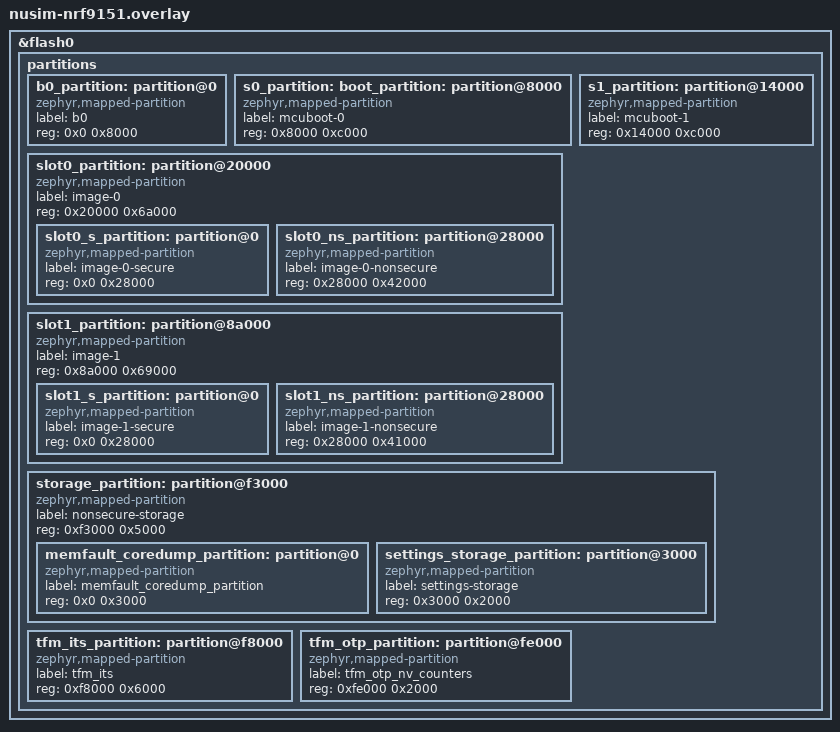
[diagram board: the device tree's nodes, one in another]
/*
 * Copyright (c) 2026 Nordic Semiconductor ASA
 *
 * SPDX-License-Identifier: LicenseRef-Nordic-5-Clause
 */

/*
 * Flash partition layout for nRF9151 DK with nuSIM (same with MCUboot and application).
 * The application SRAM layout for nuSIM is in nusim-sram-nrf9151.overlay.
 *
 * 0x0000_0000  b0 (NSIB)                    ( 32 kB)
 * 0x0000_8000  s0 (MCUboot image, slot 0)   ( 48 kB)
 * 0x0001_4000  s1 (MCUboot image, slot 1)   ( 48 kB)
 * 0x0002_0000  slot0 (primary app)          (424 kB)
 *   0x0002_0000  TF-M secure                (160 kB)
 *   0x0004_8000  Application (non-secure)   (264 kB - (MCUboot swap sector + MCUboot trailer))
 * 0x0008_a000  slot1 (secondary app)        (420 kB)
 * 0x000f_3000  storage (container)          ( 20 kB)
 *   0x000f_3000  Memfault core dump         ( 12 kB)
 *   0x000f_6000  Settings storage           (  8 kB)
 * 0x000f_8000  TF-M ITS                     ( 24 kB)
 * 0x000f_e000  TF-M OTP / NV counters       (  8 kB)
 */

&flash0 {
	/delete-node/ partitions;

	partitions {
		#address-cells = <1>;
		#size-cells = <1>;
		ranges;

		b0_partition: partition@0 {
			compatible = "zephyr,mapped-partition";
			label = "b0";
			reg = <0x0 0x8000>;
		};

		s0_partition: boot_partition: partition@8000 {
			compatible = "zephyr,mapped-partition";
			label = "mcuboot-0";
			reg = <0x8000 0xc000>;
		};

		s1_partition: partition@14000 {
			compatible = "zephyr,mapped-partition";
			label = "mcuboot-1";
			reg = <0x14000 0xc000>;
		};

		slot0_partition: partition@20000 {
			compatible = "zephyr,mapped-partition";
			label = "image-0";
			reg = <0x20000 0x6a000>;
			ranges = <0x0 0x20000 0x6a000>;
			#address-cells = <1>;
			#size-cells = <1>;

			slot0_s_partition: partition@0 {
				compatible = "zephyr,mapped-partition";
				label = "image-0-secure";
				reg = <0x0 0x28000>;
			};

			slot0_ns_partition: partition@28000 {
				compatible = "zephyr,mapped-partition";
				label = "image-0-nonsecure";
				reg = <0x28000 0x42000>;
			};
		};

		slot1_partition: partition@8a000 {
			compatible = "zephyr,mapped-partition";
			label = "image-1";
			reg = <0x8a000 0x69000>;
			ranges = <0x0 0x8a000 0x69000>;
			#address-cells = <1>;
			#size-cells = <1>;

			slot1_s_partition: partition@0 {
				compatible = "zephyr,mapped-partition";
				label = "image-1-secure";
				reg = <0x0 0x28000>;
			};

			slot1_ns_partition: partition@28000 {
				compatible = "zephyr,mapped-partition";
				label = "image-1-nonsecure";
				reg = <0x28000 0x41000>;
			};
		};

		storage_partition: partition@f3000 {
			compatible = "zephyr,mapped-partition";
			label = "nonsecure-storage";
			reg = <0xf3000 0x5000>;
			ranges = <0x0 0xf3000 0x5000>;
			#address-cells = <1>;
			#size-cells = <1>;

			memfault_coredump_partition: partition@0 {
				compatible = "zephyr,mapped-partition";
				label = "memfault_coredump_partition";
				reg = <0x0 0x3000>;
			};

			settings_storage_partition: partition@3000 {
				compatible = "zephyr,mapped-partition";
				label = "settings-storage";
				reg = <0x3000 0x2000>;
			};
		};

		tfm_its_partition: partition@f8000 {
			compatible = "zephyr,mapped-partition";
			label = "tfm_its";
			reg = <0xf8000 0x6000>;
		};

		tfm_otp_partition: partition@fe000 {
			compatible = "zephyr,mapped-partition";
			label = "tfm_otp_nv_counters";
			reg = <0xfe000 0x2000>;
		};
	};
};
